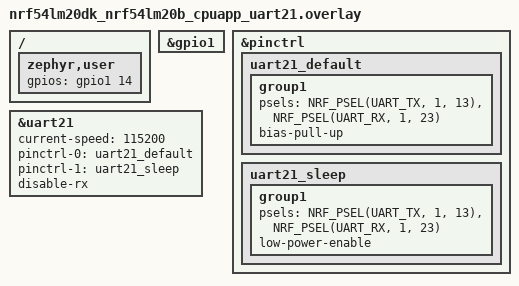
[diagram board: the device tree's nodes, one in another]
/*
 * Test requires wire connection between:
 *  - uart21 TX at P1.13 <-> GPIO input at P1.14
 */

/ {
	zephyr,user {
		gpios = <&gpio1 14 GPIO_ACTIVE_HIGH>;
	};
};

&gpio1 {
	status = "okay";
};

&pinctrl {
	uart21_default: uart21_default {
		group1 {
			psels = <NRF_PSEL(UART_TX, 1, 13)>,
				<NRF_PSEL(UART_RX, 1, 23)>;
			bias-pull-up;
		};
	};

	uart21_sleep: uart21_sleep {
		group1 {
			psels = <NRF_PSEL(UART_TX, 1, 13)>,
				<NRF_PSEL(UART_RX, 1, 23)>;
			low-power-enable;
		};
	};
};

dut: &uart21 {
	status = "okay";
	current-speed = <115200>;
	pinctrl-0 = <&uart21_default>;
	pinctrl-1 = <&uart21_sleep>;
	pinctrl-names = "default", "sleep";
	disable-rx;
};
